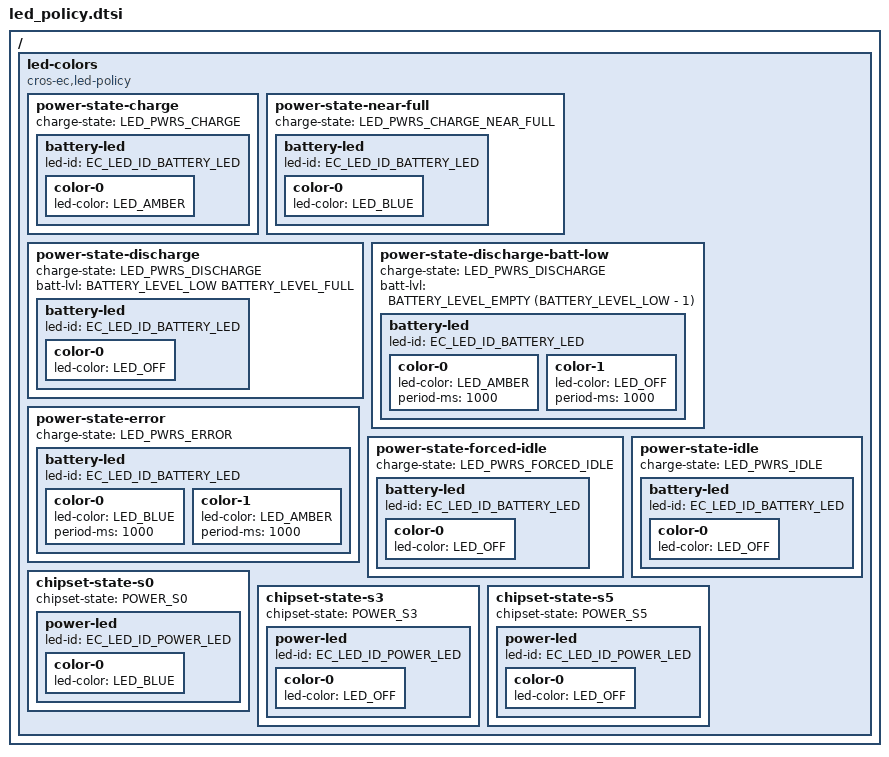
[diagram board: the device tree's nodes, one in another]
/* Copyright 2024 The ChromiumOS Authors
 * Use of this source code is governed by a BSD-style license that can be
 * found in the LICENSE file.
 */

 #include <dt-bindings/battery.h>

/ {
	led-colors {
		compatible = "cros-ec,led-policy";

		power-state-charge {
			charge-state = "LED_PWRS_CHARGE";

			battery-led {
				led-id = "EC_LED_ID_BATTERY_LED";

				color-0 {
					led-color = "LED_AMBER";
				};
			};
		};

		power-state-near-full {
			charge-state = "LED_PWRS_CHARGE_NEAR_FULL";

			battery-led {
				led-id = "EC_LED_ID_BATTERY_LED";

				color-0 {
					led-color = "LED_BLUE";
				};
			};
		};

		power-state-discharge {
			charge-state = "LED_PWRS_DISCHARGE";
			batt-lvl = <BATTERY_LEVEL_LOW BATTERY_LEVEL_FULL>;

			battery-led {
				led-id = "EC_LED_ID_BATTERY_LED";

				color-0 {
					led-color = "LED_OFF";
				};
			};
		};

		power-state-discharge-batt-low {
			charge-state = "LED_PWRS_DISCHARGE";
			batt-lvl = <BATTERY_LEVEL_EMPTY
				    (BATTERY_LEVEL_LOW - 1)>;

			battery-led {
				led-id = "EC_LED_ID_BATTERY_LED";

				/* Amber 1 sec, off 1 sec */
				color-0 {
					led-color = "LED_AMBER";
					period-ms = <1000>;
				};
				color-1 {
					led-color = "LED_OFF";
					period-ms = <1000>;
				};
			};
		};

		power-state-error {
			charge-state = "LED_PWRS_ERROR";

			battery-led {
				led-id = "EC_LED_ID_BATTERY_LED";
				/* Blue 1 sec, Amber 1 sec */
				color-0 {
					led-color = "LED_BLUE";
					period-ms = <1000>;
				};
				color-1 {
					led-color = "LED_AMBER";
					period-ms = <1000>;
				};
			};
		};


		power-state-forced-idle {
			charge-state = "LED_PWRS_FORCED_IDLE";

			battery-led {
				led-id = "EC_LED_ID_BATTERY_LED";
				color-0 {
					led-color = "LED_OFF";
				};
			};
		};

		power-state-idle {
			charge-state = "LED_PWRS_IDLE";

			battery-led {
				led-id = "EC_LED_ID_BATTERY_LED";
				color-0 {
					led-color = "LED_OFF";
				};
			};
		};

		chipset-state-s0 {
			chipset-state = "POWER_S0";

			power-led {
				led-id = "EC_LED_ID_POWER_LED";

				color-0 {
					led-color = "LED_BLUE";
				};
			};
		};

		chipset-state-s3 {
			chipset-state = "POWER_S3";

			power-led {
				led-id = "EC_LED_ID_POWER_LED";

				color-0 {
					led-color = "LED_OFF";
				};
			};
		};

		chipset-state-s5 {
			chipset-state = "POWER_S5";

			power-led {
				led-id = "EC_LED_ID_POWER_LED";

				color-0 {
					led-color = "LED_OFF";
				};
			};
		};
	};
};
